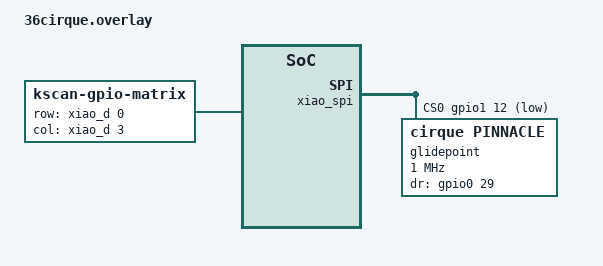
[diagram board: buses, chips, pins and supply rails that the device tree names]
// This is default overlay for the Cirque Glidepoint touchpad connected via SPI.


// &pro_micro_spi {
//     status = "okay";
//     cs-gpios = <&pro_micro 19 GPIO_ACTIVE_LOW>;

//     glidepoint: glidepoint@0 {
//         compatible = "cirque,pinnacle";
//         reg = <0>;
//         spi-max-frequency = <1000000>;
//         status = "okay";
//         dr-gpios = <&pro_micro 5 (GPIO_ACTIVE_HIGH)>;

//         sensitivity = "4x";
//         sleep;
//         no-taps;
//     };
// };
// #include <dt-bindings/zmk/input_transform.h>

// / {
//     glidepoint_listener {
//         compatible = "zmk,input-listener";
//         device = <&glidepoint>;
//         input-processors = <&zip_xy_transform (INPUT_TRANSFORM_XY_SWAP | INPUT_TRANSFORM_X_INVERT | INPUT_TRANSFORM_Y_INVERT)>;
//     };
// };
#include <dt-bindings/zmk/matrix_transform.h>

// &pinctrl {/* configuration for spi1 device, default state */
//     spi1_default: spi1_default {/* node name is arbitrary */
//         group1 {
//             /* 
//                 main role: For nice!nano, configure P0.11 as SPI clock, P0.22 as SPI MOSI, P0.08 as SPI MISO 
//                            For Xiao NRF, default pins are: P1.13 as SPI Clock, P1.15 as SPI MOSI, P1.14 as SPI MISO
//             */
//             psels = <NRF_PSEL(SPIM_SCK,  1, 13)>, // D8 (SPIM_SCK,  0, 15) between D4 & D5 would be a high speed alternate pin for the xiao plus
//                     <NRF_PSEL(SPIM_MOSI, 0, 04)>, // D4
//                     <NRF_PSEL(SPIM_MISO, 0, 05)>; // D5
//             };
//         };

//     /* configuration for spi1 device, sleep state */
//     spi1_sleep: spi1_sleep {
//         group1 {
//             /* main role: configure P0.11 as SPI clock, P0.22 as SPI MOSI, P0.08 as SPI MISO */
//             psels = <NRF_PSEL(SPIM_SCK,  1, 13)>,
//                     <NRF_PSEL(SPIM_MOSI, 0, 04)>,
//                     <NRF_PSEL(SPIM_MISO, 0, 05)>;
//             low-power-enable;
//             };
//         };
//     };
&xiao_spi {
    status = "okay";
    cs-gpios = <&gpio1 12 GPIO_ACTIVE_LOW>; // between D3 & D4
    glidepoint: glidepoint@0 {
        compatible = "cirque,pinnacle";
        reg = <0>;
        spi-max-frequency = <1000000>;
        status = "okay";
        dr-gpios = <&gpio0 29 (GPIO_ACTIVE_HIGH)>; // between D4 & D5
        // sensitivity = "3x";
        // sleep;
        no-taps;
    };
};

// / {
//     glidepoint_listener {
//         compatible = "zmk,input-listener";
//         device = <&glidepoint>;
//     };
#include <dt-bindings/zmk/input_transform.h>
#include <input/processors.dtsi>
/ {
    glidepoint_listener {
        compatible = "zmk,input-listener";
        device = <&glidepoint>;
        // input-processors = <&zip_xy_transform (INPUT_TRANSFORM_XY_SWAP)>;
        // input-processors = <&zip_xy_scaler 5 2>; //2.5 faster cursor
        // input-processors = <&zip_xy_scaler 3 1>; // 3x faster cursor
        input-processors = <&zip_xy_scaler 4 1>; // 4x faster cursor
    };
};
/ {

    chosen {
        zmk,kscan = &kscan0;
        zmk,matrix_transform = &default_transform;
    };
    
    default_transform: keymap_transform_0 {
        compatible = "zmk,matrix-transform";
        columns = <1>;
        rows = <1>;
        map = <RC(0,0)>;
    };
    
    kscan0: kscan {
        compatible = "zmk,kscan-gpio-matrix";
        label = "KSCAN";
        diode-direction = "col2row";
        row-gpios
            = <&xiao_d 0 (GPIO_ACTIVE_HIGH | GPIO_PULL_DOWN)>
            ;
        col-gpios 
            = <&xiao_d 3 GPIO_ACTIVE_HIGH>
            ;
    };
};
/* 
west build -d build/36cirque -p -b seeeduino_xiao_ble -- -DSHIELD=36cirque -DZMK_EXTRA_MODULES="/workspaces/zmk/app/cirque-input-module-main"

docker cp magical_haslett:/workspaces/zmk/app/build/36cirque/zephyr/zmk.uf2 ~/Desktop/36cirque.uf2
*/

